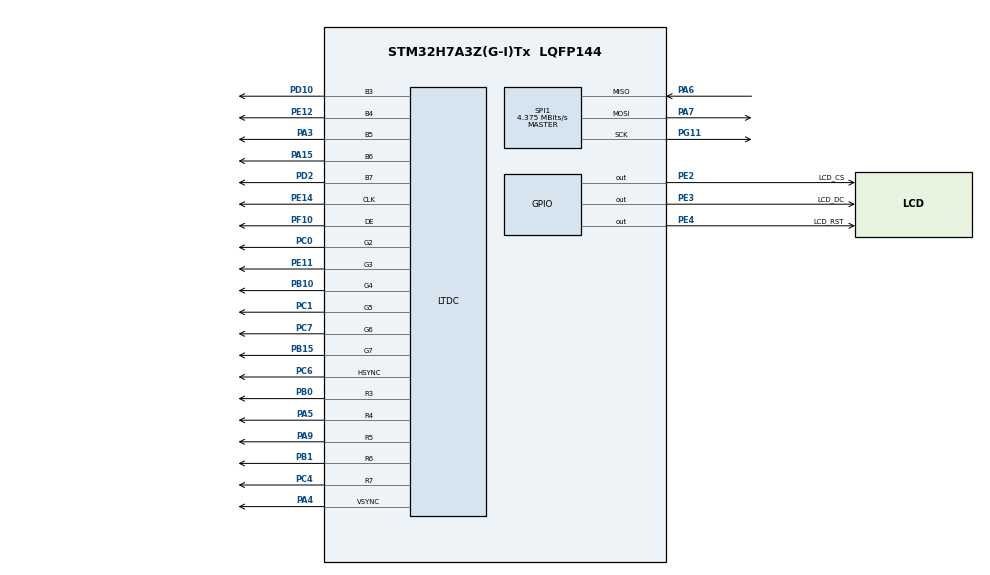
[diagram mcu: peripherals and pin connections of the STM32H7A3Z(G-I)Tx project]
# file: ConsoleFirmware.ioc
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CORTEX_M7.default_mode_Activation=1
LTDC.ActiveH=320
LTDC.ActiveW=480
LTDC.Alpha_L0=255
LTDC.PixelFormat_L0=LTDC_PIXEL_FORMAT_RGB565
LTDC.WindowX1_L0=480
LTDC.WindowY1_L0=320
Mcu.Family=STM32H7
Mcu.Name=STM32H7A3Z(G-I)Tx
Mcu.Package=LQFP144
NVIC.PriorityGroup=NVIC_PRIORITYGROUP_4
PA13.Mode=Serial_Wire
PA13.Signal=DEBUG_JTMS-SWDIO
PA14.Mode=Serial_Wire
PA14.Signal=DEBUG_JTCK-SWCLK
PA15.GPIO_Speed=GPIO_SPEED_FREQ_VERY_HIGH
PA15.Mode=RGB565
PA15.Signal=LTDC_B6
PA3.GPIO_Speed=GPIO_SPEED_FREQ_VERY_HIGH
PA3.Mode=RGB565
PA3.Signal=LTDC_B5
PA4.GPIO_Speed=GPIO_SPEED_FREQ_VERY_HIGH
PA4.Mode=RGB565
PA4.Signal=LTDC_VSYNC
PA5.GPIO_Speed=GPIO_SPEED_FREQ_VERY_HIGH
PA5.Mode=RGB565
PA5.Signal=LTDC_R4
PA6.Mode=Full_Duplex_Master
PA6.Signal=SPI1_MISO
PA7.Mode=Full_Duplex_Master
PA7.Signal=SPI1_MOSI
PA9.GPIO_Speed=GPIO_SPEED_FREQ_VERY_HIGH
PA9.Mode=RGB565
PA9.Signal=LTDC_R5
PB0.GPIO_Speed=GPIO_SPEED_FREQ_VERY_HIGH
PB0.Mode=RGB565
PB0.Signal=LTDC_R3
PB1.GPIO_Speed=GPIO_SPEED_FREQ_VERY_HIGH
PB1.Mode=RGB565
PB1.Signal=LTDC_R6
PB10.GPIO_Speed=GPIO_SPEED_FREQ_VERY_HIGH
PB10.Mode=RGB565
PB10.Signal=LTDC_G4
PB15.GPIO_Speed=GPIO_SPEED_FREQ_VERY_HIGH
PB15.Mode=RGB565
PB15.Signal=LTDC_G7
PC0.GPIO_Speed=GPIO_SPEED_FREQ_VERY_HIGH
PC0.Mode=RGB565
PC0.Signal=LTDC_G2
PC1.GPIO_Speed=GPIO_SPEED_FREQ_VERY_HIGH
PC1.Mode=RGB565
PC1.Signal=LTDC_G5
PC4.GPIO_Speed=GPIO_SPEED_FREQ_VERY_HIGH
PC4.Mode=RGB565
PC4.Signal=LTDC_R7
PC6.GPIO_Speed=GPIO_SPEED_FREQ_VERY_HIGH
PC6.Mode=RGB565
PC6.Signal=LTDC_HSYNC
PC7.GPIO_Speed=GPIO_SPEED_FREQ_VERY_HIGH
PC7.Mode=RGB565
PC7.Signal=LTDC_G6
PD10.GPIO_Speed=GPIO_SPEED_FREQ_VERY_HIGH
PD10.Mode=RGB565
PD10.Signal=LTDC_B3
PD2.GPIO_Speed=GPIO_SPEED_FREQ_VERY_HIGH
PD2.Mode=RGB565
PD2.Signal=LTDC_B7
PE11.GPIO_Speed=GPIO_SPEED_FREQ_VERY_HIGH
PE11.Mode=RGB565
PE11.Signal=LTDC_G3
PE12.GPIO_Speed=GPIO_SPEED_FREQ_VERY_HIGH
PE12.Mode=RGB565
PE12.Signal=LTDC_B4
PE14.GPIO_Speed=GPIO_SPEED_FREQ_VERY_HIGH
PE14.Mode=RGB565
PE14.Signal=LTDC_CLK
PE2.GPIO_Label=LCD_CS
PE2.GPIO_ModeDefaultOutputPP=GPIO_MODE_OUTPUT_PP
PE2.GPIO_PuPd=GPIO_NOPULL
PE2.GPIO_Speed=GPIO_SPEED_FREQ_HIGH
PE2.PinState=GPIO_PIN_SET
PE2.Signal=GPIO_Output
PE3.GPIO_Label=LCD_DC
PE3.GPIO_ModeDefaultOutputPP=GPIO_MODE_OUTPUT_PP
PE3.GPIO_PuPd=GPIO_NOPULL
PE3.GPIO_Speed=GPIO_SPEED_FREQ_HIGH
PE3.PinState=GPIO_PIN_SET
PE3.Signal=GPIO_Output
PE4.GPIO_Label=LCD_RST
PE4.GPIO_ModeDefaultOutputPP=GPIO_MODE_OUTPUT_PP
PE4.GPIO_PuPd=GPIO_NOPULL
PE4.GPIO_Speed=GPIO_SPEED_FREQ_HIGH
PE4.PinState=GPIO_PIN_SET
PE4.Signal=GPIO_Output
PF10.GPIO_Speed=GPIO_SPEED_FREQ_VERY_HIGH
PF10.Mode=RGB565
PF10.Signal=LTDC_DE
PG11.Mode=Full_Duplex_Master
PG11.Signal=SPI1_SCK
ProjectManager.HeapSize=0x200
ProjectManager.StackSize=0x400
ProjectManager.TargetToolchain=CMake
RCC.ADCFreq_Value=129000000
RCC.APB1Freq_Value=64000000
RCC.APB2Freq_Value=64000000
RCC.APB3Freq_Value=64000000
RCC.APB4Freq_Value=64000000
RCC.CortexFreq_Value=64000000
RCC.DIVN1=140
RCC.DIVQ1=4
RCC.DIVR3=32
RCC.HCLKFreq_Value=64000000
RCC.SYSCLKFreq_VALUE=64000000
RCC.USBFreq_Value=70000000
SPI1.BaudRatePrescaler=SPI_BAUDRATEPRESCALER_16
SPI1.CalculateBaudRate=4.375 MBits/s
SPI1.DataSize=SPI_DATASIZE_8BIT
SPI1.Direction=SPI_DIRECTION_2LINES
SPI1.Mode=SPI_MODE_MASTER
SPI1.VirtualType=VM_MASTER
VP_MEMORYMAP_VS_MEMORYMAP.Mode=CurAppReg
board=custom

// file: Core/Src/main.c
/* USER CODE BEGIN Header */
/**
  ******************************************************************************
  * @file           : main.c
  * @brief          : Main program body
  ******************************************************************************
  * @attention
  *
  * Copyright (c) 2026 STMicroelectronics.
  * All rights reserved.
  *
  * This software is licensed under terms that can be found in the LICENSE file
  * in the root directory of this software component.
  * If no LICENSE file comes with this software, it is provided AS-IS.
  *
  ******************************************************************************
  */
/* USER CODE END Header */
#include "main.h"
#include "ltdc.h"
#include "spi.h"
#include "gpio.h"
#include "console.h"

void SystemClock_Config(void);
static void MPU_Config(void);

int main(void)
{

  /* MPU Configuration--------------------------------------------------------*/
  MPU_Config();

  /* MCU Configuration--------------------------------------------------------*/

  /* Reset of all peripherals, Initializes the Flash interface and the Systick. */
  HAL_Init();

  /* Configure the system clock */
  SystemClock_Config();

  /* Initialize all configured peripherals */
  MX_GPIO_Init();
  MX_LTDC_Init();
  MX_SPI1_Init();
  /* USER CODE BEGIN 2 */
  console_init();

  /* USER CODE END 2 */

  /* Infinite loop */
  while (1)
  {

  }
}

void SystemClock_Config(void)
{
  RCC_OscInitTypeDef RCC_OscInitStruct = {0};
  RCC_ClkInitTypeDef RCC_ClkInitStruct = {0};

  /*AXI clock gating */
  RCC->CKGAENR = 0xE003FFFF;

  /** Supply configuration update enable
  */
  HAL_PWREx_ConfigSupply(PWR_LDO_SUPPLY);

  /** Configure the main internal regulator output voltage
  */
  __HAL_PWR_VOLTAGESCALING_CONFIG(PWR_REGULATOR_VOLTAGE_SCALE3);

  while(!__HAL_PWR_GET_FLAG(PWR_FLAG_VOSRDY)) {}

  /** Initializes the RCC Oscillators according to the specified parameters
  * in the RCC_OscInitTypeDef structure.
  */
  RCC_OscInitStruct.OscillatorType = RCC_OSCILLATORTYPE_HSI;
  RCC_OscInitStruct.HSIState = RCC_HSI_DIV1;
  RCC_OscInitStruct.HSICalibrationValue = 64;
  RCC_OscInitStruct.PLL.PLLState = RCC_PLL_ON;
  RCC_OscInitStruct.PLL.PLLSource = RCC_PLLSOURCE_HSI;
  RCC_OscInitStruct.PLL.PLLM = 32;
  RCC_OscInitStruct.PLL.PLLN = 140;
  RCC_OscInitStruct.PLL.PLLP = 2;
  RCC_OscInitStruct.PLL.PLLQ = 4;
  RCC_OscInitStruct.PLL.PLLR = 2;
  RCC_OscInitStruct.PLL.PLLRGE = RCC_PLL1VCIRANGE_1;
  RCC_OscInitStruct.PLL.PLLVCOSEL = RCC_PLL1VCOWIDE;
  RCC_OscInitStruct.PLL.PLLFRACN = 0;
  if (HAL_RCC_OscConfig(&RCC_OscInitStruct) != HAL_OK)
  {
    Error_Handler();
  }

  /** Initializes the CPU, AHB and APB buses clocks
  */
  RCC_ClkInitStruct.ClockType = RCC_CLOCKTYPE_HCLK|RCC_CLOCKTYPE_SYSCLK
                              |RCC_CLOCKTYPE_PCLK1|RCC_CLOCKTYPE_PCLK2
                              |RCC_CLOCKTYPE_D3PCLK1|RCC_CLOCKTYPE_D1PCLK1;
  RCC_ClkInitStruct.SYSCLKSource = RCC_SYSCLKSOURCE_HSI;
  RCC_ClkInitStruct.SYSCLKDivider = RCC_SYSCLK_DIV1;
  RCC_ClkInitStruct.AHBCLKDivider = RCC_HCLK_DIV1;
  RCC_ClkInitStruct.APB3CLKDivider = RCC_APB3_DIV1;
  RCC_ClkInitStruct.APB1CLKDivider = RCC_APB1_DIV1;
  RCC_ClkInitStruct.APB2CLKDivider = RCC_APB2_DIV1;
  RCC_ClkInitStruct.APB4CLKDivider = RCC_APB4_DIV1;

  if (HAL_RCC_ClockConfig(&RCC_ClkInitStruct, FLASH_LATENCY_2) != HAL_OK)
  {
    Error_Handler();
  }
}

 /* MPU Configuration */

void MPU_Config(void)
{
  MPU_Region_InitTypeDef MPU_InitStruct = {0};

  /* Disables the MPU */
  HAL_MPU_Disable();

  /** Initializes and configures the Region and the memory to be protected
  */
  MPU_InitStruct.Enable = MPU_REGION_ENABLE;
  MPU_InitStruct.Number = MPU_REGION_NUMBER0;
  MPU_InitStruct.BaseAddress = 0x0;
  MPU_InitStruct.Size = MPU_REGION_SIZE_4GB;
  MPU_InitStruct.SubRegionDisable = 0x87;
  MPU_InitStruct.TypeExtField = MPU_TEX_LEVEL0;
  MPU_InitStruct.AccessPermission = MPU_REGION_NO_ACCESS;
  MPU_InitStruct.DisableExec = MPU_INSTRUCTION_ACCESS_DISABLE;
  MPU_InitStruct.IsShareable = MPU_ACCESS_SHAREABLE;
  MPU_InitStruct.IsCacheable = MPU_ACCESS_NOT_CACHEABLE;
  MPU_InitStruct.IsBufferable = MPU_ACCESS_NOT_BUFFERABLE;

  HAL_MPU_ConfigRegion(&MPU_InitStruct);
  /* Enables the MPU */
  HAL_MPU_Enable(MPU_PRIVILEGED_DEFAULT);

}

void Error_Handler(void)
{
  __disable_irq();
  while (1)
  {
  }
}
